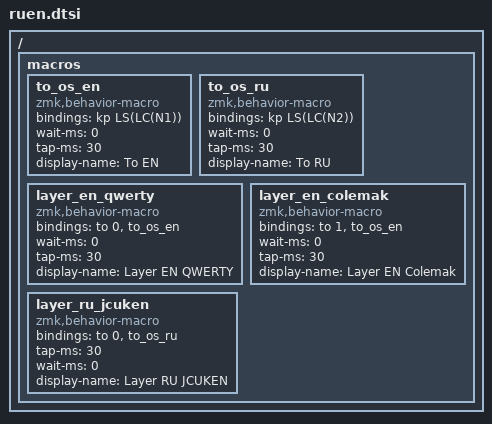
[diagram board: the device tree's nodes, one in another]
#include <behaviors.dtsi>

/ {
    macros {
        to_os_en: to_os_en {
            compatible = "zmk,behavior-macro";
            #binding-cells = <0>;
            bindings = <&kp LS(LC(N1))>;
            wait-ms = <0>;
            tap-ms = <30>;

            display-name = "To EN";
        };

        to_os_ru: to_os_ru {
            compatible = "zmk,behavior-macro";
            #binding-cells = <0>;
            bindings = <&kp LS(LC(N2))>;
            wait-ms = <0>;
            tap-ms = <30>;

            display-name = "To RU";
        };

        layer_en_qwerty: layer_en_qwerty {
            compatible = "zmk,behavior-macro";
            #binding-cells = <0>;
            bindings = <&to 0 &to_os_en>;
            wait-ms = <0>;
            tap-ms = <30>;

            display-name = "Layer EN QWERTY";
        };

        layer_en_colemak: layer_en_colemak {
            compatible = "zmk,behavior-macro";
            #binding-cells = <0>;
            bindings = <&to 1 &to_os_en>;
            wait-ms = <0>;
            tap-ms = <30>;

            display-name = "Layer EN Colemak";
        };

        layer_ru_jcuken: layer_ru_jcuken {
            compatible = "zmk,behavior-macro";
            #binding-cells = <0>;
            bindings = <&to 0 &to_os_ru>;
            tap-ms = <30>;
            wait-ms = <0>;

            display-name = "Layer RU JCUKEN";
        };
    };
};
